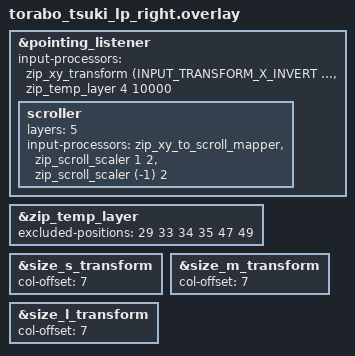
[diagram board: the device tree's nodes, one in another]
#include "torabo_tsuki_lp.dtsi"
#include <input/processors.dtsi>
#include <dt-bindings/zmk/input_transform.h>

&pointing_listener {
    /* 通常時の入力プロセッサ：反転処理 ＋ オートマウスレイヤー（レイヤー4）の発動設定 */
    input-processors = <&zip_xy_transform (INPUT_TRANSFORM_X_INVERT | INPUT_TRANSFORM_Y_INVERT)>, <&zip_temp_layer 4 10000>;

    /* 【新設】レイヤー5の時だけ、トラックボールの動きをスクロール（ホイール信号）に変換 */
    scroller {
        layers = <5>;
        input-processors = <&zip_xy_to_scroll_mapper>, <&zip_scroll_scaler 1 2>, <&zip_scroll_scaler (-1) 2>;
    };
};

&zip_temp_layer {
    excluded-positions = <
        29 // g
        33 // J
        34 // K
        35 // l
        47 // m
        49 // .
    >;
};

&size_s_transform { col-offset = <7>; };
&size_m_transform { col-offset = <7>; };
&size_l_transform { col-offset = <7>; };
